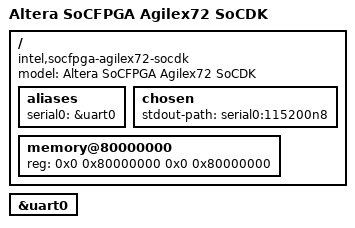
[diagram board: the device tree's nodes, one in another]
// SPDX-License-Identifier: GPL-2.0-only
/*
 * Copyright (C) 2026, Altera Corporation
 */
#include "socfpga_agilex72.dtsi"

/ {
	model = "Altera SoCFPGA Agilex72 SoCDK";
	compatible = "intel,socfpga-agilex72-socdk", "intel,socfpga-agilex72";

	aliases {
		serial0 = &uart0;
	};

	chosen {
		stdout-path = "serial0:115200n8";
	};

	memory@80000000 {
		device_type = "memory";
		reg = <0x0 0x80000000 0x0 0x80000000>;
	};
};

&uart0 {
	status = "okay";
};
